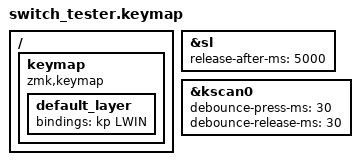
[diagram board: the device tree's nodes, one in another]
#include <behaviors.dtsi>
#include <dt-bindings/zmk/keys.h>

#define DEFAULT 0

&sl { release-after-ms = <5000>; };

&kscan0 {
    debounce-press-ms = <30>;
    debounce-release-ms = <30>;
};

/ {
    keymap {
        compatible = "zmk,keymap";

        default_layer {
            bindings = <
&kp LWIN
            >;
        };
    };
};
